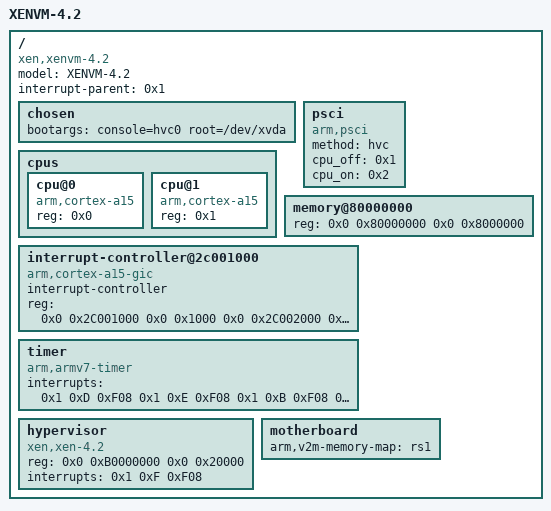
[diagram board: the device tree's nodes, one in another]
/dts-v1/;
// version: 17
// last_comp_version: 16
// boot_cpuid_phys: 0x0

/ {
    model = "XENVM-4.2";
    compatible = "xen,xenvm-4.2", "xen,xenvm";
    interrupt-parent = <0x1>;
    #address-cells = <0x2>;
    #size-cells = <0x2>;
    chosen {
        bootargs = "console=hvc0 root=/dev/xvda";
    };
    cpus {
        #address-cells = <0x1>;
        #size-cells = <0x0>;
        cpu@0 {
            device_type = "cpu";
            compatible = "arm,cortex-a15";
            reg = <0x0>;
        };
        cpu@1 {
            device_type = "cpu";
            compatible = "arm,cortex-a15";
            reg = <0x1>;
        };
    };
    psci {
        compatible = "arm,psci";
        method = "hvc";
        cpu_off = <0x1>;
        cpu_on = <0x2>;
    };
    memory@80000000 {
        device_type = "memory";
        reg = <0x0 0x80000000 0x0 0x8000000>;
    };
    interrupt-controller@2c001000 {
        compatible = "arm,cortex-a15-gic", "arm,cortex-a9-gic";
        #interrupt-cells = <0x3>;
        #address-cells = <0x0>;
        interrupt-controller;
        reg = <0x0 0x2C001000 0x0 0x1000 0x0 0x2C002000 0x0 0x100>;
        phandle = <0x1>;
    };
    timer {
        compatible = "arm,armv7-timer";
        interrupts = <0x1 0xD 0xF08 0x1 0xE 0xF08 0x1 0xB 0xF08 0x1 0xA 0xF08>;
    };
    hypervisor {
        compatible = "xen,xen-4.2", "xen,xen";
        reg = <0x0 0xB0000000 0x0 0x20000>;
        interrupts = <0x1 0xF 0xF08>;
    };
    motherboard {
        arm,v2m-memory-map = "rs1";
    };
    __symbols__ {
        gic = "/interrupt-controller@2c001000";
    };
};
